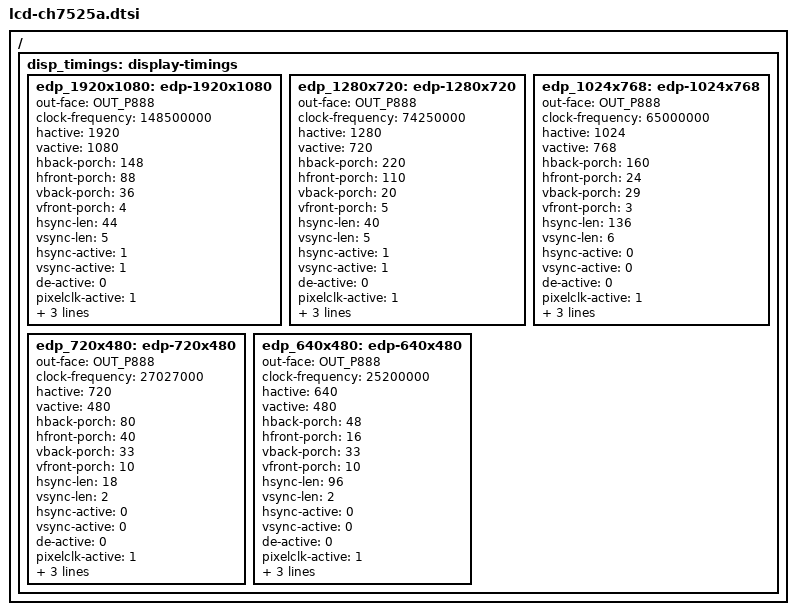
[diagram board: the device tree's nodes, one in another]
/*
 * Advantech. eDP to hdmi chip ch7525a
 *
 */
/ {
	disp_timings: display-timings {
		edp_1920x1080: edp-1920x1080 {
			out-face    = <OUT_P888>;
			clock-frequency = <148500000>;
			hactive = <1920>;
			vactive = <1080>;
			hback-porch = <148>;
			hfront-porch = <88>;
			vback-porch = <36>;
			vfront-porch = <4>;
			hsync-len = <44>;
			vsync-len = <5>;
			hsync-active = <1>;
			vsync-active = <1>;
			de-active = <0>;
			pixelclk-active = <1>;
			swap-rb = <0>;
			swap-rg = <0>;
			swap-gb = <0>;
		};
		edp_1280x720: edp-1280x720 {
			out-face    = <OUT_P888>;
			clock-frequency = <74250000>;
			hactive = <1280>;
			vactive = <720>;
			hback-porch = <220>;
			hfront-porch = <110>;
			vback-porch = <20>;
			vfront-porch = <5>;
			hsync-len = <40>;
			vsync-len = <5>;
			hsync-active = <1>;
			vsync-active = <1>;
			de-active = <0>;
			pixelclk-active = <1>;
			swap-rb = <0>;
			swap-rg = <0>;
			swap-gb = <0>;
		};
		edp_1024x768: edp-1024x768 {
			out-face    = <OUT_P888>;
			clock-frequency = <65000000>;
			hactive = <1024>;
			vactive = <768>;
			hback-porch = <160>;
			hfront-porch = <24>;
			vback-porch = <29>;
			vfront-porch = <3>;
			hsync-len = <136>;
			vsync-len = <6>;
			hsync-active = <0>;
			vsync-active = <0>;
			de-active = <0>;
			pixelclk-active = <1>;
			swap-rb = <0>;
			swap-rg = <0>;
			swap-gb = <0>;
		};
		edp_720x480: edp-720x480 {
			out-face    = <OUT_P888>;
			clock-frequency = <27027000>;
			hactive = <720>;
			vactive = <480>;
			hback-porch = <80>;
			hfront-porch = <40>;
			vback-porch = <33>;
			vfront-porch = <10>;
			hsync-len = <18>;
			vsync-len = <2>;
			hsync-active = <0>;
			vsync-active = <0>;
			de-active = <0>;
			pixelclk-active = <1>;
			swap-rb = <0>;
			swap-rg = <0>;
			swap-gb = <0>;
		};
		edp_640x480: edp-640x480 {
			out-face    = <OUT_P888>;
			clock-frequency = <25200000>;
			hactive = <640>;
			vactive = <480>;
			hback-porch = <48>;
			hfront-porch = <16>;
			vback-porch = <33>;
			vfront-porch = <10>;
			hsync-len = <96>;
			vsync-len = <2>;
			hsync-active = <0>;
			vsync-active = <0>;
			de-active = <0>;
			pixelclk-active = <1>;
			swap-rb = <0>;
			swap-rg = <0>;
			swap-gb = <0>;
		};
	};
};
